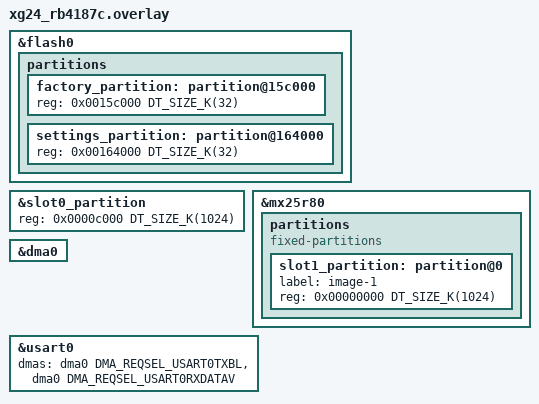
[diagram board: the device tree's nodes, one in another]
/*
 *    Copyright (c) 2026 Project CHIP Authors
 *    All rights reserved.
 *
 *    Licensed under the Apache License, Version 2.0 (the "License");
 *    you may not use this file except in compliance with the License.
 *    You may obtain a copy of the License at
 *
 *        http://www.apache.org/licenses/LICENSE-2.0
 *    Unless required by applicable law or agreed to in writing, software
 *    distributed under the License is distributed on an "AS IS" BASIS
 *    WITHOUT WARRANTIES OR CONDITIONS OF ANY KIND, either express or implied.
 *    See the License for the specific language governing permissions and
 *    limitations under the License.
 */



&flash0 {
    partitions {
        factory_partition: partition@15c000 {
                reg = <0x0015c000 DT_SIZE_K(32)>;
        };
        settings_partition: partition@164000 {
                reg = <0x00164000 DT_SIZE_K(32)>;
        };
    };
};

&slot0_partition {
    reg = <0x0000c000 DT_SIZE_K(1024)>;
};

/* The board defines slot1 on internal flash0; remove it and recreate it on the
 * external SPI NOR below. storage_partition keeps its board-default location
 * (0x178000) so its node name still matches its reg base. */
/delete-node/ &slot1_partition;

&mx25r80 {
    partitions {
        compatible = "fixed-partitions";
        #address-cells = <1>;
        #size-cells = <1>;

        slot1_partition: partition@0 {
            label = "image-1";
            reg = <0x00000000 DT_SIZE_K(1024)>;
        };
    };
};

&dma0 {
	status = "okay";
};

&usart0 {
    dmas = <&dma0 DMA_REQSEL_USART0TXBL>,
           <&dma0 DMA_REQSEL_USART0RXDATAV>;
    dma-names = "tx", "rx";
};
